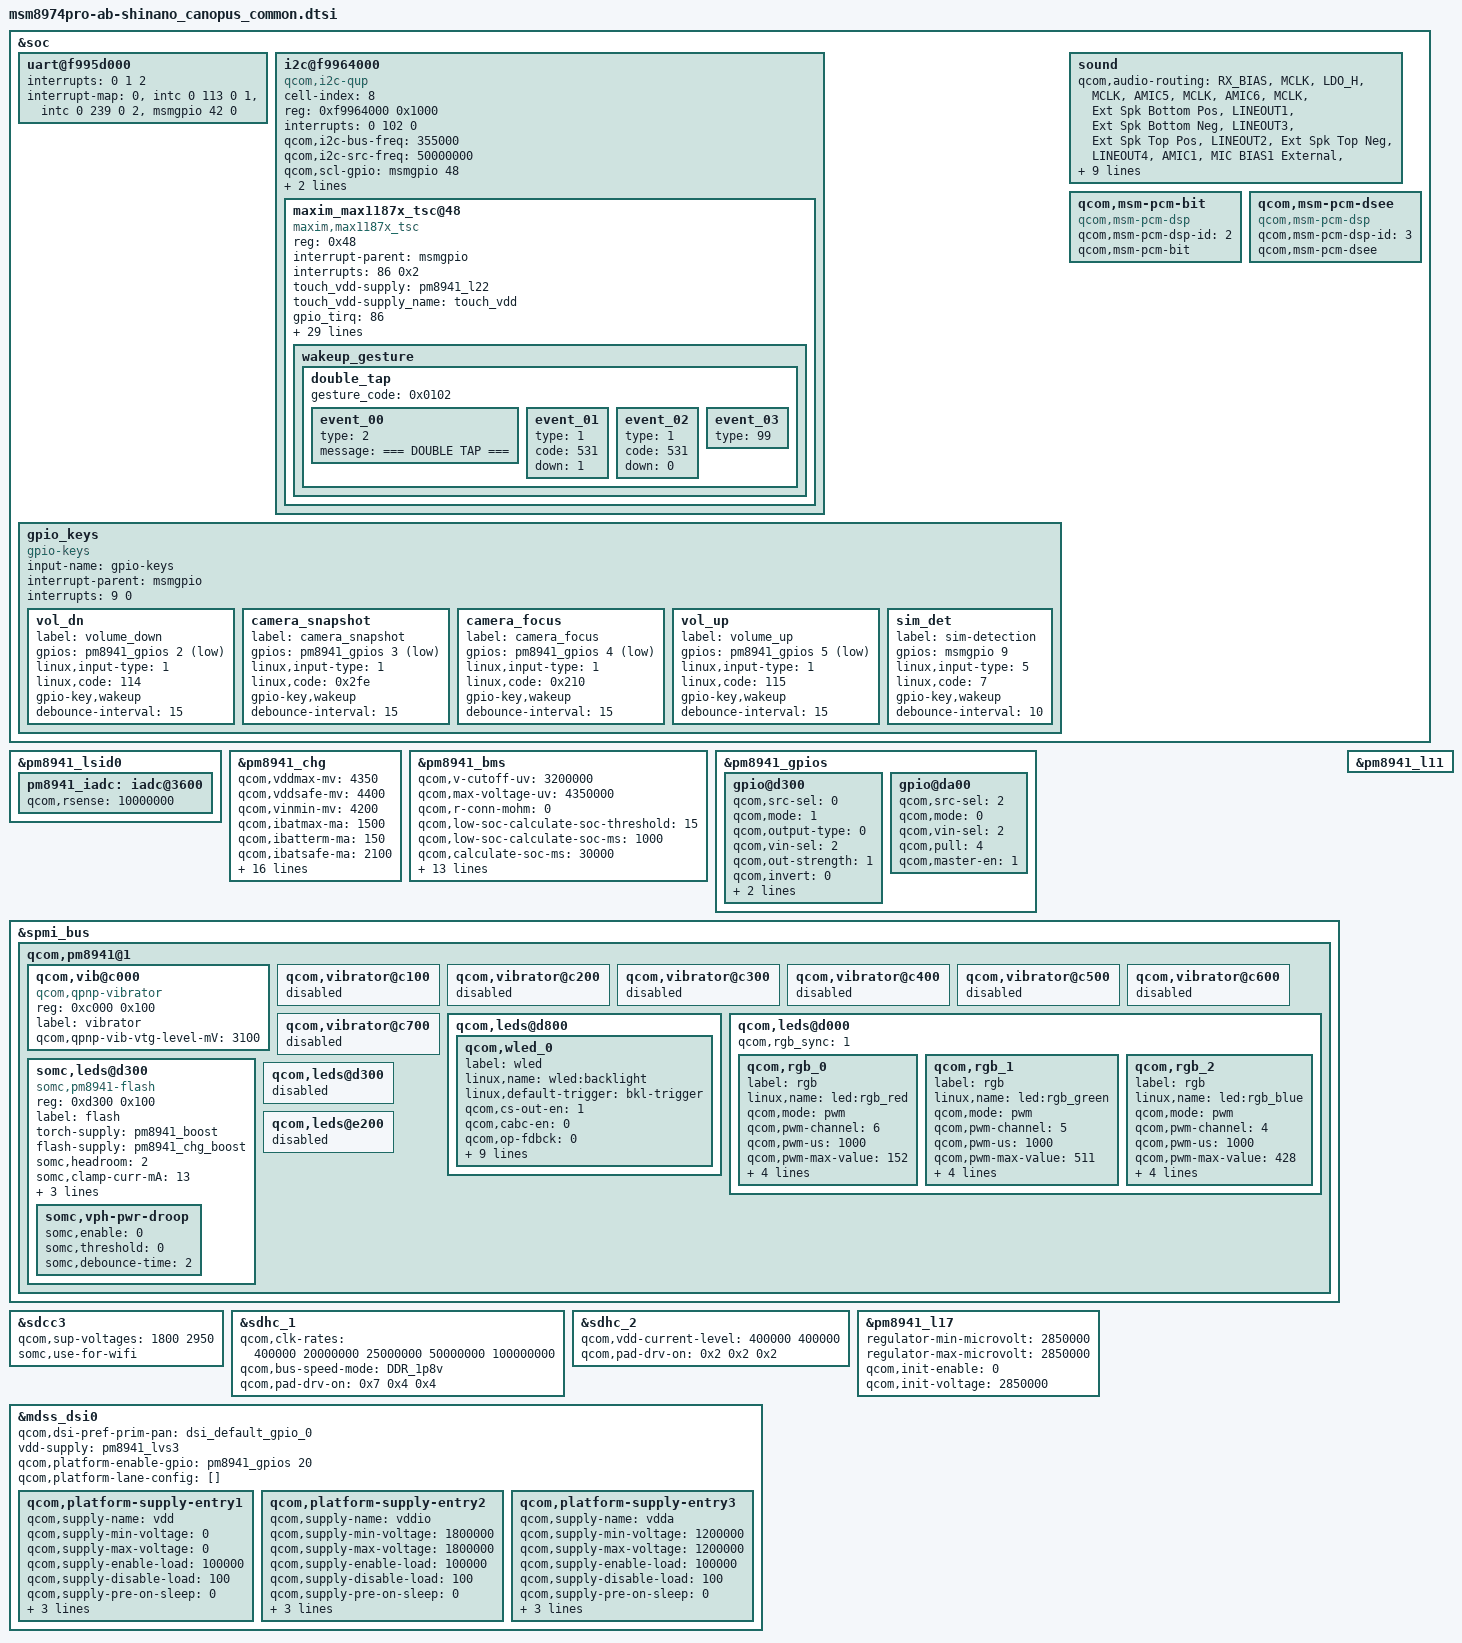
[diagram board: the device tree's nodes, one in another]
/* arch/arm/boot/dts/msm8974pro-ab-shinano_canopus_common.dtsi
 *
 * Copyright (C) 2014 Sony Mobile Communications Inc.
 *
 * This program is free software; you can redistribute it and/or modify
 * it under the terms of the GNU General Public License version 2 and
 * only version 2 as published by the Free Software Foundation.
 *
 * This program is distributed in the hope that it will be useful,
 * but WITHOUT ANY WARRANTY; without even the implied warranty of
 * MERCHANTABILITY or FITNESS FOR A PARTICULAR PURPOSE.  See the
 * GNU General Public License for more details.
 */

&soc {
	/* UART : BLSP7 */
	uart@f995d000 {
		interrupt-names = "core_irq", "bam_irq", "wakeup_irq";
		interrupts = <0 1 2>;
		interrupt-map = <0 &intc 0 113 0
				 1 &intc 0 239 0
				 2 &msmgpio 42 0>;
	};

	/* I2C : BLSP8 */
	i2c@f9964000 {
		cell-index = <8>;
		compatible = "qcom,i2c-qup";
		reg = <0xf9964000 0x1000>;
		#address-cells = <1>;
		#size-cells = <0>;
		reg-names = "qup_phys_addr";
		interrupts = <0 102 0>;
		interrupt-names = "qup_err_intr";
		qcom,i2c-bus-freq = <355000>;
		qcom,i2c-src-freq = <50000000>;
		qcom,scl-gpio = <&msmgpio 48 0x00>;
		qcom,sda-gpio = <&msmgpio 47 0x00>;
		qcom,master-id = <84>;
		status = "ok";
		maxim_max1187x_tsc@48 {
			compatible = "maxim,max1187x_tsc";
			reg = <0x48>;
			interrupt-parent = <&msmgpio>;
			interrupts = <86 0x2>;
			touch_vdd-supply = <&pm8941_l22>;
			touch_vdd-supply_name = "touch_vdd";
			gpio_tirq = <86>;
			gpio_reset = <85>;
			reset_l2h = <1>;
			enable_resume_por = <1>;
			defaults_allow = <0>;
			default_config_id = <0>;
			default_chip_id = <0>;
			fw_name = "touch_chip_id_0x%02x_config_id_0x%%04x.bin";
			i2c_words = <128>;
			coordinate_settings = <0x4>;
			panel_margin_xl = <0>;
			lcd_x = <1080>;
			panel_margin_xh = <0>;
			panel_margin_yl = <0>;
			lcd_y = <1920>;
			panel_margin_yh = <0>;
			num_sensor_x = <20>;
			num_sensor_y = <34>;
			button_code0 = <0>;
			button_code1 = <0>;
			button_code2 = <0>;
			button_code3 = <0>;
			touch_pressure_enabled = <1>;
			touch_size_enabled = <0>;
			touch_orientation_enabled = <0>;
			glove_enabled = <0>;
			report_pen_as_finger = <1>;
			wakeup_gesture_support = <1>;
			wakeup_gesture_timeout = <2000>;
			wakeup_gesture {
				double_tap {
					gesture_code = <0x0102>;
					event_00 {
						type = <2>; /* LOG */
						message = "=== DOUBLE TAP ===";
					};
					event_01 {
						type = <1>; /* KEY */
						code = <531>; /* TOUCHPAD_ON */
						down = <1>;
					};
					event_02 {
						type = <1>; /* KEY */
						code = <531>; /* TOUCHPAD_ON */
						down = <0>;
					};
					event_03 {
						type = <99>; /* END */
					};
				};
			};
		};
	};

	gpio_keys {
		compatible = "gpio-keys";
		input-name = "gpio-keys";
		interrupt-parent = <&msmgpio>;
		interrupts = <9 0>;

		vol_dn {
			label = "volume_down";
			gpios = <&pm8941_gpios 2 0x1>;
			linux,input-type = <1>;
			linux,code = <114>;
			gpio-key,wakeup;
			debounce-interval = <15>;
		};

		camera_snapshot {
			label = "camera_snapshot";
			gpios = <&pm8941_gpios 3 0x1>;
			linux,input-type = <1>;
			linux,code = <0x2fe>;
			gpio-key,wakeup;
			debounce-interval = <15>;
		};

		camera_focus {
			label = "camera_focus";
			gpios = <&pm8941_gpios 4 0x1>;
			linux,input-type = <1>;
			linux,code = <0x210>;
			gpio-key,wakeup;
			debounce-interval = <15>;
		};

		vol_up {
			label = "volume_up";
			gpios = <&pm8941_gpios 5 0x1>;
			linux,input-type = <1>;
			linux,code = <115>;
			gpio-key,wakeup;
			debounce-interval = <15>;
		};

		sim_det {
			label = "sim-detection";
			gpios = <&msmgpio 9 0x0>;
			linux,input-type = <5>;
			linux,code = <7>;
			gpio-key,wakeup;
			debounce-interval = <10>;
		};
	};

	sound {
		qcom,audio-routing =
			"RX_BIAS", "MCLK",
			"LDO_H", "MCLK",
			"AMIC5", "MCLK",
			"AMIC6", "MCLK",
			"Ext Spk Bottom Pos", "LINEOUT1",
			"Ext Spk Bottom Neg", "LINEOUT3",
			"Ext Spk Top Pos", "LINEOUT2",
			"Ext Spk Top Neg", "LINEOUT4",
			"AMIC1", "MIC BIAS1 External",
			"MIC BIAS1 External", "Secondary Mic",
			"AMIC2", "MIC BIAS2 External",
			"MIC BIAS2 External", "Headset Mic",
			"MIC BIAS2 External", "ANCRight Headset Mic",
			"AMIC3", "MIC BIAS3 External",
			"MIC BIAS3 External", "ANCLeft Headset Mic",
			"AMIC4", "MIC BIAS1 External",
			"MIC BIAS1 External", "Handset Mic";
		qcom,mbhc-audio-jack-type = "5-pole-jack";
	};

	qcom,msm-pcm-bit {
		compatible = "qcom,msm-pcm-dsp";
		qcom,msm-pcm-dsp-id = <2>;
		qcom,msm-pcm-bit;
	};

	qcom,msm-pcm-dsee {
		compatible = "qcom,msm-pcm-dsp";
		qcom,msm-pcm-dsp-id = <3>;
		qcom,msm-pcm-dsee;
	};
};

&pm8941_lsid0 {
	pm8941_iadc: iadc@3600 {
		qcom,rsense = <10000000>;
	};
};

&pm8941_chg {
	qcom,vddmax-mv = <4350>;
	qcom,vddsafe-mv = <4400>;
	qcom,vinmin-mv = <4200>;
	qcom,ibatmax-ma = <1500>;
	qcom,ibatterm-ma = <150>;
	qcom,ibatsafe-ma = <2100>;
	qcom,maxinput-dc-ma = <1800>;
	qcom,maxinput-dc-mv = <10000>;
	qcom,maxinput-usb-ma = <1500>;
	qcom,maxinput-usb-mv = <13000>;
	qcom,thermal-mitigation = <3000 2100 1800 1500 1200 900 600 300 100 0>;
	qcom,cool-bat-mv = <4350>;
	qcom,ibatmax-warm-ma = <900>;
	qcom,warm-bat-mv = <4200>;
	qcom,ibatmax-cool-ma = <900>;
	qcom,vbatdet-delta-mv = <60>;
	qcom,tchg-mins = <512>;
	qcom,vbatweak-mv = <3200>;
	qcom,step-thresh-soc = <50>;
	qcom,ibatmax-ma-over-step = <1500>;
	qcom,ibatmax-ma-under-step = <2100>;
};

&pm8941_bms {
	qcom,v-cutoff-uv = <3200000>;
	qcom,max-voltage-uv = <4350000>;
	qcom,r-conn-mohm = <0>;
	qcom,low-soc-calculate-soc-threshold = <15>;
	qcom,low-soc-calculate-soc-ms = <1000>;
	qcom,calculate-soc-ms = <30000>;
	qcom,chg-term-ua = <150000>;
	qcom,use-external-rsense;
	qcom,batt-type = <3>;
	qcom,use-ocv-thresholds;
	qcom,ocv-voltage-high-threshold-uv = <3840000>;
	qcom,ocv-voltage-low-threshold-uv = <3750000>;
	qcom,shutdown-soc-valid-limit = <40>;
	qcom,enable-fcc-learning;
	qcom,min-fcc-learning-soc = <20>;
	qcom,min-fcc-ocv-pc = <30>;
	qcom,min-fcc-learning-samples = <5>;
	qcom,fcc-resolution = <13>;
	qcom,clamp-soc-max-count = <2>;
};

&pm8941_gpios {
	/* GPIO_20: LCD_DCDC_EN */
	gpio@d300 {
		qcom,src-sel = <0>;		/* GPIO */
		qcom,mode = <1>;		/* Out */
		qcom,output-type = <0>;		/* CMOS */
		qcom,vin-sel = <2>;		/* S3 */
		qcom,out-strength = <1>;	/* Low */
		qcom,invert = <0>;		/* Low */
		qcom,master-en = <1>;		/* Enable */
		somc,keep_high_at_init;
		status = "ok";
	};

	/* GPIO_27: FLASH_LED_NOW */
	gpio@da00 {
		qcom,src-sel = <2>;		/* Alternate function 1 */
		qcom,mode = <0>;		/* In */
		qcom,vin-sel = <2>;		/* S3 */
		qcom,pull = <4>;		/* PD */
		qcom,master-en = <1>;		/* Enable */
		status = "ok";
	};
};

&spmi_bus {
	qcom,pm8941@1 {
		qcom,vib@c000 {
			status = "okay";
			compatible = "qcom,qpnp-vibrator";
			reg = <0xc000 0x100>;
			label = "vibrator";
			qcom,qpnp-vib-vtg-level-mV = <3100>;
		};

		qcom,vibrator@c100 {
			status = "disabled";
		};

		qcom,vibrator@c200 {
			status = "disabled";
		};

		qcom,vibrator@c300 {
			status = "disabled";
		};

		qcom,vibrator@c400 {
			status = "disabled";
		};

		qcom,vibrator@c500 {
			status = "disabled";
		};

		qcom,vibrator@c600 {
			status = "disabled";
		};

		qcom,vibrator@c700 {
			status = "disabled";
		};
	};
};

&sdcc3 {
	qcom,sup-voltages = <1800 2950>;
	somc,use-for-wifi;
	status = "ok";
};

&sdhc_1 {
	qcom,clk-rates = <400000 20000000 25000000 50000000 100000000>;
	qcom,bus-speed-mode = "DDR_1p8v";
	qcom,pad-drv-on = <0x7 0x4 0x4>; /* 16mA, 10mA, 10mA */
};

&sdhc_2 {
	qcom,vdd-current-level = <400000 400000>;
	qcom,pad-drv-on = <0x2 0x2 0x2>; /* 6mA, 6mA, 6mA */
};

&spmi_bus {
	qcom,pm8941@1 {
		qcom,leds@d800 {
			status = "okay";
			qcom,wled_0 {
				label = "wled";
				linux,name = "wled:backlight";
				linux,default-trigger = "bkl-trigger";
				qcom,cs-out-en = <1>;
				qcom,cabc-en = <0>;
				qcom,op-fdbck = <0>;
				qcom,default-state = "on";
				qcom,max-current = <20>;
				qcom,ctrl-delay-us = <0>;
				qcom,boost-curr-lim = <3>;
				qcom,cp-sel = <0>;
				qcom,switch-freq = <2>;
				qcom,ovp-val = <2>;
				qcom,num-strings = <2>;
				qcom,id = <0>;
			};
		};

		qcom,leds@d000 {
			status = "okay";
			qcom,rgb_sync = <1>;

			qcom,rgb_0 {
				label = "rgb";
				linux,name = "led:rgb_red";
				qcom,mode = "pwm";
				qcom,pwm-channel = <6>;
				qcom,pwm-us = <1000>;
				qcom,pwm-max-value = <152>;
				qcom,max-current = <12>;
				qcom,default-state = "off";
				qcom,id = <3>;
				linux,default-trigger = "none";
			};

			qcom,rgb_1 {
				label = "rgb";
				linux,name = "led:rgb_green";
				qcom,mode = "pwm";
				qcom,pwm-channel = <5>;
				qcom,pwm-us = <1000>;
				qcom,pwm-max-value = <511>;
				qcom,max-current = <12>;
				qcom,default-state = "off";
				qcom,id = <4>;
				linux,default-trigger = "none";
			};

			qcom,rgb_2 {
				label = "rgb";
				linux,name = "led:rgb_blue";
				qcom,mode = "pwm";
				qcom,pwm-channel = <4>;
				qcom,pwm-us = <1000>;
				qcom,pwm-max-value = <428>;
				qcom,max-current = <12>;
				qcom,default-state = "off";
				qcom,id = <5>;
				linux,default-trigger = "none";
			};
		};

		somc,leds@d300 {
			status = "okay";
			compatible = "somc,pm8941-flash";
			reg = <0xd300 0x100>;
			label = "flash";
			torch-supply = <&pm8941_boost>;
			flash-supply = <&pm8941_chg_boost>;
			somc,headroom = <2>;
			somc,clamp-curr-mA = <13>;
			somc,startup-dly = <3>;
			somc,hw-strobe-config = <3>;
			somc,mask-enable = <1>;
			somc,vph-pwr-droop {
				somc,enable = <0>;
				somc,threshold = <0>;
				somc,debounce-time = <2>;
			};
		};

		qcom,leds@d300 {
			status = "disabled";
		};

		qcom,leds@e200 {
			status = "disabled";
		};
	};
};

/* Regulator config */
&pm8941_l11 {
	status = "ok";
};

&pm8941_l17 {
	regulator-min-microvolt = <2850000>;
	regulator-max-microvolt = <2850000>;
	qcom,init-enable = <0>;
	qcom,init-voltage = <2850000>;
	status = "ok";
};

&mdss_dsi0 {
	qcom,dsi-pref-prim-pan = <&dsi_default_gpio_0>;
	vdd-supply = <&pm8941_lvs3>;
	qcom,platform-enable-gpio = <&pm8941_gpios 20 0>;
	qcom,platform-lane-config = [];
	qcom,platform-supply-entry1 {
			qcom,supply-name = "vdd";
			qcom,supply-min-voltage = <0>;
			qcom,supply-max-voltage = <0>;
			qcom,supply-enable-load = <100000>;
			qcom,supply-disable-load = <100>;
			qcom,supply-pre-on-sleep = <0>;
			qcom,supply-post-on-sleep = <0>;
			qcom,supply-pre-off-sleep = <0>;
			qcom,supply-post-off-sleep = <0>;
	};
	qcom,platform-supply-entry2 {
			qcom,supply-name = "vddio";
			qcom,supply-min-voltage = <1800000>;
			qcom,supply-max-voltage = <1800000>;
			qcom,supply-enable-load = <100000>;
			qcom,supply-disable-load = <100>;
			qcom,supply-pre-on-sleep = <0>;
			qcom,supply-post-on-sleep = <0>;
			qcom,supply-pre-off-sleep = <0>;
			qcom,supply-post-off-sleep = <0>;
	};
	qcom,platform-supply-entry3 {
			qcom,supply-name = "vdda";
			qcom,supply-min-voltage = <1200000>;
			qcom,supply-max-voltage = <1200000>;
			qcom,supply-enable-load = <100000>;
			qcom,supply-disable-load = <100>;
			qcom,supply-pre-on-sleep = <0>;
			qcom,supply-post-on-sleep = <0>;
			qcom,supply-pre-off-sleep = <0>;
			qcom,supply-post-off-sleep = <0>;
	};
};
